# STM32H7S3xx register map
File version: 1.0
Registers are 32-bit, read-write, reset 0x0 unless marked. A register's access mark holds for its fields unless they carry their own. Offsets are from the block's base; [hi:lo] are bit positions; 'fields as' and 'values as' point back to an identical list.

## FMC_Bank1_R — Flexible Memory Controller Bank1
Base 0x52004000
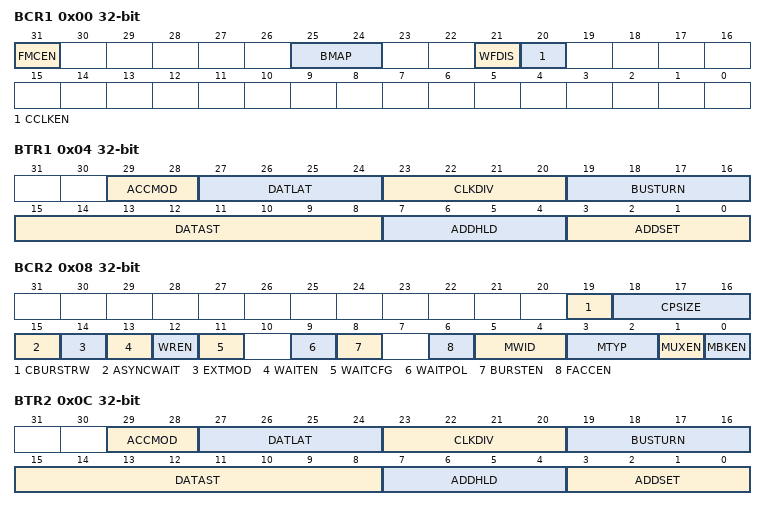
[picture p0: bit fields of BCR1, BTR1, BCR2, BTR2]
0x00 BCR1 — NOR/PSRAM chip-select control register(BCR) and chip-select timing register(BTR)
  [31] FMCEN — FMC controller enable
  [25:24] BMAP — FMC bank mapping
  [21] WFDIS — Write FIFO Disable
  [20] CCLKEN — Continuous clock enable
0x04 BTR1 — NOR/PSRAM chip-select control register(BCR) and chip-select timing register(BTR)
  [29:28] ACCMOD — Access mode
  [27:24] DATLAT — Data latency for synchronous memory
  [23:20] CLKDIV — Clock divide ratio
  [19:16] BUSTURN — Bus turnaround phase duration
  [15:8] DATAST — Data-phase duration
  [7:4] ADDHLD — Address-hold phase duration
  [3:0] ADDSET — Address setup phase duration
0x08 BCR2 — NOR/PSRAM chip-select control register(BCR) and chip-select timing register(BTR)
  [19] CBURSTRW — Write burst enable
  [18:16] CPSIZE — CRAM page size
  [15] ASYNCWAIT — Wait signal during asynchronous transfers
  [14] EXTMOD — Extended mode enable
  [13] WAITEN — Wait enable bit
  [12] WREN — Write enable bit
  [11] WAITCFG — Wait timing configuration
  [9] WAITPOL — Wait signal polarity bit
  [8] BURSTEN — Burst enable bit
  [6] FACCEN — Flash access enable
  [5:4] MWID — Memory data bus width
  [3:2] MTYP — Memory type
  [1] MUXEN — Address/data multiplexing enable bit
  [0] MBKEN — Memory bank enable bit
0x0C BTR2 — NOR/PSRAM chip-select control register(BCR) and chip-select timing register(BTR)
  fields as BTR1
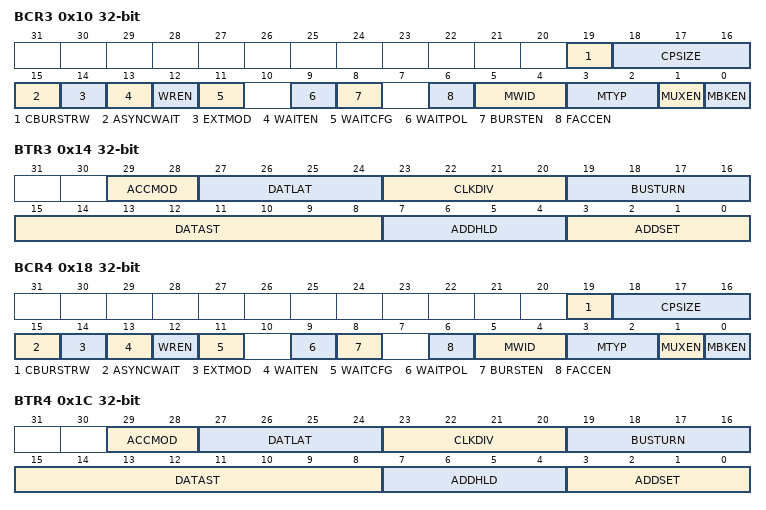
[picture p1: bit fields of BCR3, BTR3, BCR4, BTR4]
0x10 BCR3 — NOR/PSRAM chip-select control register(BCR) and chip-select timing register(BTR)
  fields as BCR2
0x14 BTR3 — NOR/PSRAM chip-select control register(BCR) and chip-select timing register(BTR)
  fields as BTR1
0x18 BCR4 — NOR/PSRAM chip-select control register(BCR) and chip-select timing register(BTR)
  fields as BCR2
0x1C BTR4 — NOR/PSRAM chip-select control register(BCR) and chip-select timing register(BTR)
  fields as BTR1

## FMC_Bank3_R — Flexible Memory Controller Bank3
Base 0x52004080
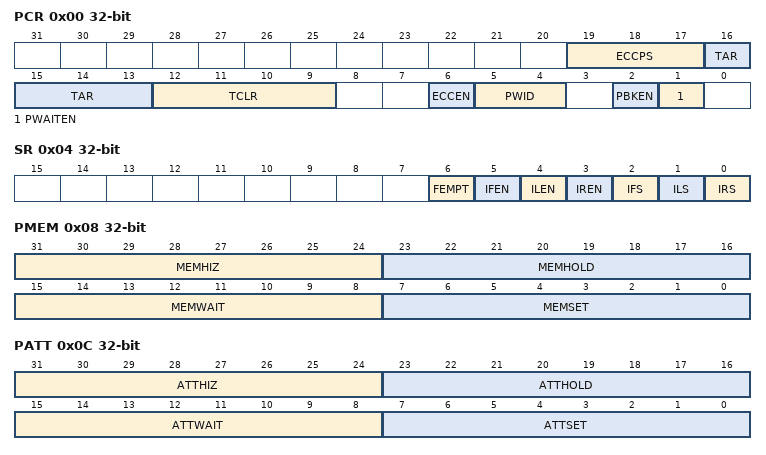
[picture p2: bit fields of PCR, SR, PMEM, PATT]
0x00 PCR — NAND Flash control register
  [19:17] ECCPS — ECC page size
  [16:13] TAR — ALE to RE delay
  [12:9] TCLR — CLE to RE delay
  [6] ECCEN — ECC computation logic enable bit
  [5:4] PWID — Data bus width
  [2] PBKEN — NAND Flash memory bank enable bit
  [1] PWAITEN — Wait feature enable bit
0x04 SR — NAND Flash FIFO status and interrupt register
  [6] FEMPT — FIFO empty
  [5] IFEN — Interrupt falling edge detection enable bit
  [4] ILEN — Interrupt high-level detection enable bit
  [3] IREN — Interrupt rising edge detection enable bit
  [2] IFS — Interrupt falling edge status
  [1] ILS — Interrupt high-level status
  [0] IRS — Interrupt rising edge status
0x08 PMEM — NAND Flash Common memory space timing register
  [31:24] MEMHIZ — Common memory databus Hi-Z time
  [23:16] MEMHOLD — Common memory hold time
  [15:8] MEMWAIT — Common memory wait time
  [7:0] MEMSET — Common memory setup time
0x0C PATT — NAND Flash Attribute memory space timing register
  [31:24] ATTHIZ — Attribute memory data bus Hi-Z time
  [23:16] ATTHOLD — Attribute memory hold time
  [15:8] ATTWAIT — Attribute memory wait time
  [7:0] ATTSET — Attribute memory setup time
0x14 ECCR — NAND Flash ECC result registers
  [31:0] ECC — ECC result

## FMC_Bank1E_R — Flexible Memory Controller Bank1 Extended
Base 0x52004104
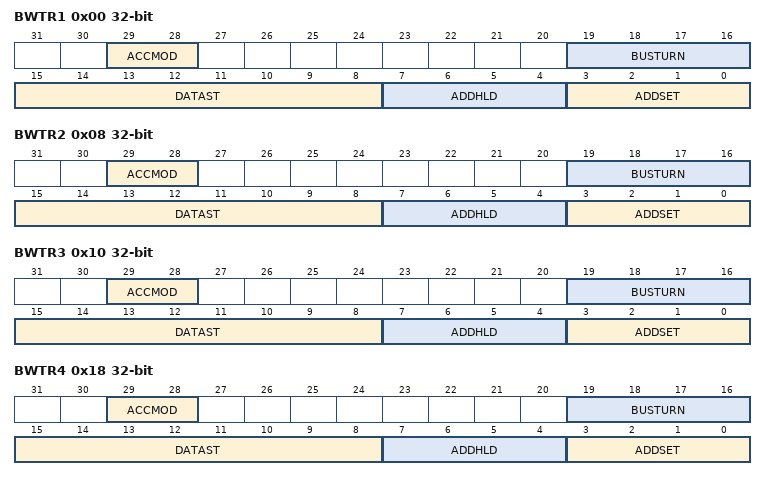
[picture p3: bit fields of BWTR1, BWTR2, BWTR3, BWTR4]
0x00 BWTR1 — NOR/PSRAM write timing registers
  [29:28] ACCMOD — Access mode
  [19:16] BUSTURN — Bus turnaround phase duration
  [15:8] DATAST — Data-phase duration
  [7:4] ADDHLD — Address-hold phase duration
  [3:0] ADDSET — Address setup phase duration
0x08 BWTR2 — NOR/PSRAM write timing registers
  fields as BWTR1
0x10 BWTR3 — NOR/PSRAM write timing registers
  fields as BWTR1
0x18 BWTR4 — NOR/PSRAM write timing registers
  fields as BWTR1
